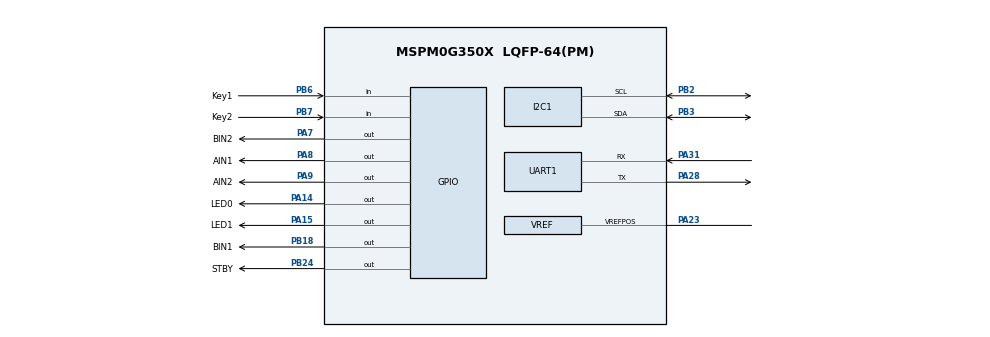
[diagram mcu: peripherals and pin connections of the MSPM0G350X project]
/**
 * @cliArgs --device "MSPM0G350X" --part "Default" --package "LQFP-64(PM)" --product "mspm0_sdk@2.10.00.04"
 * @versions {"tool":"1.26.2+4477"}
 */

/**
 * Import the modules used in this configuration.
 */
const ADC12  = scripting.addModule("/ti/driverlib/ADC12", {}, false);
const ADC121 = ADC12.addInstance();
const GPIO   = scripting.addModule("/ti/driverlib/GPIO", {}, false);
const GPIO1  = GPIO.addInstance();
const GPIO2  = GPIO.addInstance();
const GPIO3  = GPIO.addInstance();
const I2C    = scripting.addModule("/ti/driverlib/I2C", {}, false);
const I2C1   = I2C.addInstance();
const PWM    = scripting.addModule("/ti/driverlib/PWM", {}, false);
const PWM1   = PWM.addInstance();
const SYSCTL = scripting.addModule("/ti/driverlib/SYSCTL");
const UART   = scripting.addModule("/ti/driverlib/UART", {}, false);
const UART1  = UART.addInstance();
const VREF   = scripting.addModule("/ti/driverlib/VREF");

/**
 * Write custom configuration values to the imported modules.
 */
const divider9       = system.clockTree["UDIV"];
divider9.divideValue = 2;

const multiplier2         = system.clockTree["PLL_QDIV"];
multiplier2.multiplyValue = 5;

const mux4       = system.clockTree["EXHFMUX"];
mux4.inputSelect = "EXHFMUX_XTAL";

const mux8       = system.clockTree["HSCLKMUX"];
mux8.inputSelect = "HSCLKMUX_SYSPLL0";

const pinFunction4     = system.clockTree["HFXT"];
pinFunction4.inputFreq = 40;

ADC121.$name                      = "POT";
ADC121.repeatMode                 = true;
ADC121.adcMem0vref                = "VREF";
ADC121.adcMem0chansel             = "DL_ADC12_INPUT_CHAN_1";
ADC121.peripheral.adcPin1.$assign = "PA16";
ADC121.adcPin1Config.$name        = "ti_driverlib_gpio_GPIOPinGeneric4";

const Board = scripting.addModule("/ti/driverlib/Board", {}, false);

GPIO1.$name                         = "LED";
GPIO1.associatedPins.create(2);
GPIO1.associatedPins[0].$name       = "LED1";
GPIO1.associatedPins[0].pin.$assign = "PA15";
GPIO1.associatedPins[1].$name       = "LED0";
GPIO1.associatedPins[1].pin.$assign = "PA14";

GPIO2.$name                              = "Key";
GPIO2.associatedPins.create(2);
GPIO2.associatedPins[0].$name            = "Key1";
GPIO2.associatedPins[0].direction        = "INPUT";
GPIO2.associatedPins[0].assignedPort     = "PORTB";
GPIO2.associatedPins[0].internalResistor = "PULL_DOWN";
GPIO2.associatedPins[0].interruptEn      = true;
GPIO2.associatedPins[0].polarity         = "RISE";
GPIO2.associatedPins[0].pin.$assign      = "PB6";
GPIO2.associatedPins[1].$name            = "Key2";
GPIO2.associatedPins[1].direction        = "INPUT";
GPIO2.associatedPins[1].assignedPort     = "PORTB";
GPIO2.associatedPins[1].internalResistor = "PULL_DOWN";
GPIO2.associatedPins[1].interruptEn      = true;
GPIO2.associatedPins[1].polarity         = "RISE";
GPIO2.associatedPins[1].pin.$assign      = "PB7";

GPIO3.$name                         = "Motor";
GPIO3.associatedPins.create(5);
GPIO3.associatedPins[0].$name       = "AIN1";
GPIO3.associatedPins[0].pin.$assign = "PA8";
GPIO3.associatedPins[1].$name       = "AIN2";
GPIO3.associatedPins[1].pin.$assign = "PA9";
GPIO3.associatedPins[2].$name       = "STBY";
GPIO3.associatedPins[2].pin.$assign = "PB24";
GPIO3.associatedPins[3].$name       = "BIN1";
GPIO3.associatedPins[3].pin.$assign = "PB18";
GPIO3.associatedPins[4].$name       = "BIN2";
GPIO3.associatedPins[4].pin.$assign = "PA7";

I2C1.$name                             = "OLED";
I2C1.basicEnableController             = true;
I2C1.advDigitalGlitchFilter            = "CLOCKS_1";
I2C1.advControllerRXFIFOTRIG           = "BYTES_8";
I2C1.advControllerTXFIFOTRIG           = "BYTES_7";
I2C1.enableDMAEvent1                   = false;
I2C1.enableDMAEvent2                   = false;
I2C1.peripheral.$assign                = "I2C1";
I2C1.peripheral.sdaPin.$assign         = "PB3";
I2C1.peripheral.sclPin.$assign         = "PB2";
I2C1.sdaPinConfig.hideOutputInversion  = scripting.forceWrite(false);
I2C1.sdaPinConfig.onlyInternalResistor = scripting.forceWrite(false);
I2C1.sdaPinConfig.passedPeripheralType = scripting.forceWrite("Digital");
I2C1.sdaPinConfig.$name                = "ti_driverlib_gpio_GPIOPinGeneric0";
I2C1.sdaPinConfig.enableConfig         = true;
I2C1.sdaPinConfig.internalResistor     = "PULL_UP";
I2C1.sclPinConfig.hideOutputInversion  = scripting.forceWrite(false);
I2C1.sclPinConfig.onlyInternalResistor = scripting.forceWrite(false);
I2C1.sclPinConfig.passedPeripheralType = scripting.forceWrite("Digital");
I2C1.sclPinConfig.$name                = "ti_driverlib_gpio_GPIOPinGeneric1";
I2C1.sclPinConfig.enableConfig         = true;
I2C1.sclPinConfig.internalResistor     = "PULL_UP";

PWM1.$name                              = "PWM1";
PWM1.timerCount                         = 4000;
PWM1.timerStartTimer                    = true;
PWM1.pwmMode                            = "EDGE_ALIGN_UP";
PWM1.PWM_CHANNEL_0.$name                = "ti_driverlib_pwm_PWMTimerCC0";
PWM1.ccp0PinConfig.direction            = scripting.forceWrite("OUTPUT");
PWM1.ccp0PinConfig.hideOutputInversion  = scripting.forceWrite(false);
PWM1.ccp0PinConfig.onlyInternalResistor = scripting.forceWrite(false);
PWM1.ccp0PinConfig.passedPeripheralType = scripting.forceWrite("Digital");
PWM1.ccp0PinConfig.$name                = "ti_driverlib_gpio_GPIOPinGeneric6";
PWM1.peripheral.$assign                 = "TIMG0";
PWM1.PWM_CHANNEL_1.$name                = "ti_driverlib_pwm_PWMTimerCC1";
PWM1.ccp1PinConfig.$name                = "ti_driverlib_gpio_GPIOPinGeneric7";

SYSCTL.forceDefaultClkConfig = true;
SYSCTL.clockTreeEn           = true;

UART1.$name                            = "Serial";
UART1.targetBaudRate                   = 115200;
UART1.enabledInterrupts                = ["RX"];
UART1.peripheral.$assign               = "UART0";
UART1.peripheral.rxPin.$assign         = "PA31";
UART1.peripheral.txPin.$assign         = "PA28";
UART1.txPinConfig.direction            = scripting.forceWrite("OUTPUT");
UART1.txPinConfig.hideOutputInversion  = scripting.forceWrite(false);
UART1.txPinConfig.onlyInternalResistor = scripting.forceWrite(false);
UART1.txPinConfig.passedPeripheralType = scripting.forceWrite("Digital");
UART1.txPinConfig.$name                = "ti_driverlib_gpio_GPIOPinGeneric2";
UART1.rxPinConfig.hideOutputInversion  = scripting.forceWrite(false);
UART1.rxPinConfig.onlyInternalResistor = scripting.forceWrite(false);
UART1.rxPinConfig.passedPeripheralType = scripting.forceWrite("Digital");
UART1.rxPinConfig.$name                = "ti_driverlib_gpio_GPIOPinGeneric3";

VREF.peripheral.vrefPosPin.$assign = "PA23";
VREF.vrefPosPinConfig.$name        = "ti_driverlib_gpio_GPIOPinGeneric5";

/**
 * Pinmux solution for unlocked pins/peripherals. This ensures that minor changes to the automatic solver in a future
 * version of the tool will not impact the pinmux you originally saw.  These lines can be completely deleted in order to
 * re-solve from scratch.
 */
ADC121.peripheral.$suggestSolution         = "ADC1";
Board.peripheral.$suggestSolution          = "DEBUGSS";
Board.peripheral.swclkPin.$suggestSolution = "PA20";
Board.peripheral.swdioPin.$suggestSolution = "PA19";
PWM1.peripheral.ccp0Pin.$suggestSolution   = "PA12";
PWM1.peripheral.ccp1Pin.$suggestSolution   = "PA13";
VREF.peripheral.$suggestSolution           = "VREF";
